AUTOSAR XML (schema 4-0-3)
package /Application
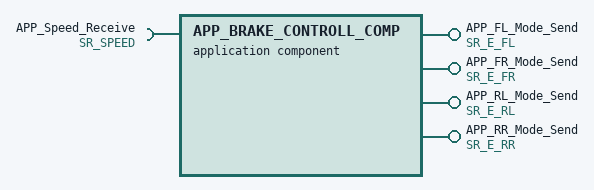
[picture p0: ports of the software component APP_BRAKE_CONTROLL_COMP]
  application sw component type APP_BRAKE_CONTROLL_COMP
    require port APP_Speed_Receive: required-interface=SR_SPEED
    4 x provide port:
      APP_FL_Mode_Send: provided-interface=SR_E_FL
      APP_FR_Mode_Send: provided-interface=SR_E_FR
      APP_RL_Mode_Send: provided-interface=SR_E_RL
      APP_RR_Mode_Send: provided-interface=SR_E_RR
    behavior IB_BRAKE_CONTROLLER
      4 x data received event:
        DataReceivedEvent_0: start-on-event=RE_APP_FL_DATA_RECEV, data=APP_Speed_Receive.frontleft
        DataReceivedEvent_1: start-on-event=RE_APP_FR_DATA_RECEV, data=APP_Speed_Receive.frontright
        DataReceivedEvent_2: start-on-event=RE_APP_RL_DATA_RECEV, data=APP_Speed_Receive.backleft
        DataReceivedEvent_3: start-on-event=RE_APP_RR_DATA_RECEV, data=APP_Speed_Receive.backright
      4 x runnable:
        RE_APP_FL_DATA_RECEV: symbol=RE_APP_FL_DATA_RECEV_func
          data-receive-point-by-values:
            access DRPV_frontleft_0: accessed-variable=APP_Speed_Receive.frontleft
          data-send-points:
            access DSP_modedata_0: accessed-variable=APP_FL_Mode_Send.modedata
        RE_APP_FR_DATA_RECEV: symbol=RE_APP_FR_DATA_RECEV_func
          data-receive-point-by-values:
            access DRPV_frontright_0: accessed-variable=APP_Speed_Receive.frontright
          data-send-points:
            access DSP_modedata_0: accessed-variable=APP_FR_Mode_Send.modedata
        RE_APP_RL_DATA_RECEV: symbol=RE_APP_RL_DATA_RECEV_func
          data-receive-point-by-values:
            access DRPV_backleft_0: accessed-variable=APP_Speed_Receive.backleft
          data-send-points:
            access DSP_modedata_0: accessed-variable=APP_RL_Mode_Send.modedata
        RE_APP_RR_DATA_RECEV: symbol=RE_APP_RR_DATA_RECEV_func
          data-receive-point-by-values:
            access DRPV_backright_0: accessed-variable=APP_Speed_Receive.backright
          data-send-points:
            access DSP_modedata_0: accessed-variable=APP_RR_Mode_Send.modedata
  5 x sender receiver interface:
    SR_SPEED
      4 x data, all with type=float32:
        frontleft
        frontright
        backleft
        backright
    SR_E_FL
      data modedata: type=sint8
    SR_E_FR
      data modedata: type=sint8
    SR_E_RL
      data modedata: type=sint8
    SR_E_RR
      data modedata: type=sint8
